# Cortex_M85 register map
Vendor: ARM Ltd.; File version: 1.0
Cortex-M85 core descriptions, generated from ARM developer studio
CPU: CM85 r0p0, little endian, MPU, FPU, vendor SysTick, 8 interrupt priority bits
Registers are 32-bit, read-write, no defined reset value unless marked. A register's access mark holds for its fields unless they carry their own. Offsets are from the block's base; lines under a group give offsets from that group; [hi:lo] are bit positions; {n}, {i} and the like mark numbered series; 'fields as' and 'values as' point back to an identical list; <NAME> marks a mode.

## Memory map
0xE000E004 ICB size 0x60 — Interrupt Control Registers
0xE000E010 SYST size 0x180 — SysTick Control Registers
0xE000E100 NVIC size 0x205DC — Nested Vectored Interrupt Controller registers
0xE000ED00 SCB size 0x20090 — System Control Block
0xE000ED90 MPU size 0x20038 — Memory protection Unit Control Registers
0xE000EDD0 SAU size 0xE0 — Security Attribute Unit
0xE000EDF0 DCB size 0x20010 — Debug Registers
0xE000EF00 SIG size 0x20004 — Software Interrupt Control
0xE000EF34 FPE size 0x20018 — Floating Point Control Registers

## DCB — Debug Registers
Base 0xE000EDF0
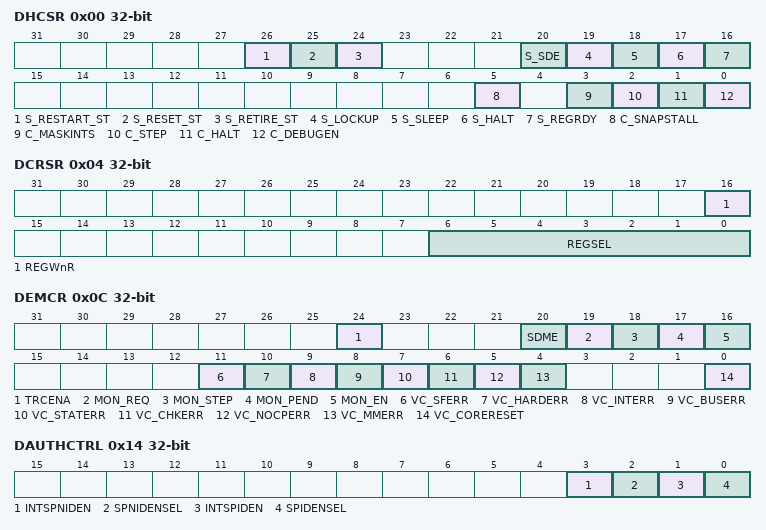
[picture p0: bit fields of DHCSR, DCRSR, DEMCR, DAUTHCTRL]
0x00 DHCSR
  [26] S_RESTART_ST, [25] S_RESET_ST, [24] S_RETIRE_ST, [20] S_SDE, [19] S_LOCKUP, [18] S_SLEEP, [17] S_HALT, [16] S_REGRDY, [5] C_SNAPSTALL, [3] C_MASKINTS, [2] C_STEP, [1] C_HALT, [0] C_DEBUGEN
0x04 DCRSR wo
  [16] REGWnR, [6:0] REGSEL
0x08 DCRDR
  [31:0] DBGTMP
0x0C DEMCR ro
  [24] TRCENA, [20] SDME, [19] MON_REQ, [18] MON_STEP, [17] MON_PEND, [16] MON_EN, [11] VC_SFERR, [10] VC_HARDERR, [9] VC_INTERR, [8] VC_BUSERR, [7] VC_STATERR, [6] VC_CHKERR, [5] VC_NOCPERR, [4] VC_MMERR, [0] VC_CORERESET
0x14 DAUTHCTRL
  [3] INTSPNIDEN, [2] SPNIDENSEL, [1] INTSPIDEN, [0] SPIDENSEL
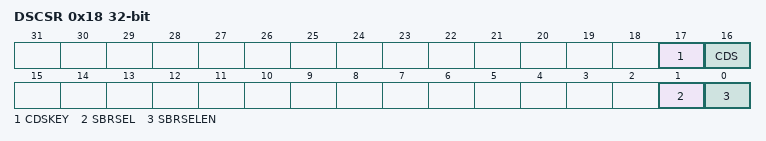
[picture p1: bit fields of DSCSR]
0x18 DSCSR ro
  [17] CDSKEY, [16] CDS, [1] SBRSEL, [0] SBRSELEN

## FPE — Floating Point Control Registers
Base 0xE000EF34
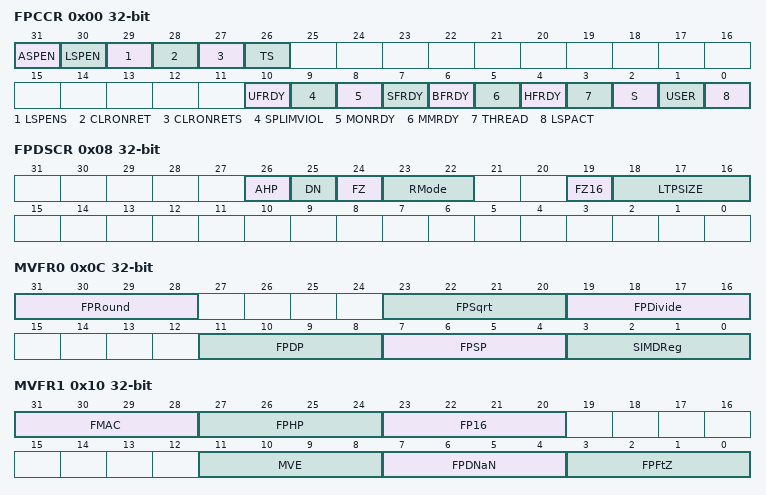
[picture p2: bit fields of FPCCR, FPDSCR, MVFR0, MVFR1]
0x00 FPCCR
  [31] ASPEN, [30] LSPEN, [29] LSPENS, [28] CLRONRET, [27] CLRONRETS, [26] TS, [10] UFRDY, [9] SPLIMVIOL, [8] MONRDY, [7] SFRDY, [6] BFRDY, [5] MMRDY, [4] HFRDY, [3] THREAD, [2] S, [1] USER, [0] LSPACT
0x04 FPCAR
  [31:3] ADDRESS
0x08 FPDSCR
  [26] AHP, [25] DN, [24] FZ, [23:22] RMode, [19] FZ16, [18:16] LTPSIZE
0x0C MVFR0 ro
  [31:28] FPRound, [23:20] FPSqrt, [19:16] FPDivide, [11:8] FPDP, [7:4] FPSP, [3:0] SIMDReg
0x10 MVFR1 ro
  [31:28] FMAC, [27:24] FPHP, [23:20] FP16, [11:8] MVE, [7:4] FPDNaN, [3:0] FPFtZ
0x14 MVFR2 ro
  [7:4] FPMisc

## ICB — Interrupt Control Registers
Base 0xE000E004
0x00 ICTR ro
  [3:0] INTLINESNUM
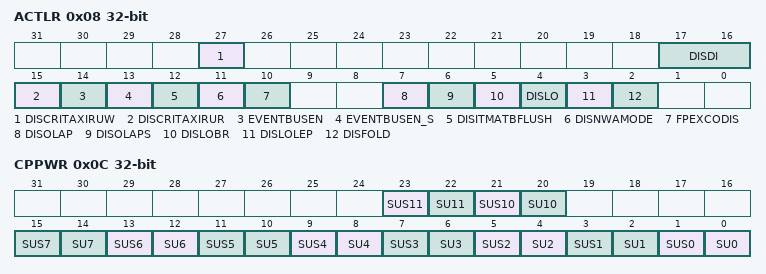
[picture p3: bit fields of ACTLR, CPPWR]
0x08 ACTLR
  [27] DISCRITAXIRUW, [17:16] DISDI, [15] DISCRITAXIRUR, [14] EVENTBUSEN, [13] EVENTBUSEN_S, [12] DISITMATBFLUSH, [11] DISNWAMODE, [10] FPEXCODIS, [7] DISOLAP, [6] DISOLAPS, [5] DISLOBR, [4] DISLO, [3] DISLOLEP, [2] DISFOLD
0x0C CPPWR
  [23] SUS11, [22] SU11, [21] SUS10, [20] SU10, [2n+1] SUS{n} (n=0..7), [2n] SU{n} (n=0..7)

## MPU — Memory protection Unit Control Registers
Base 0xE000ED90
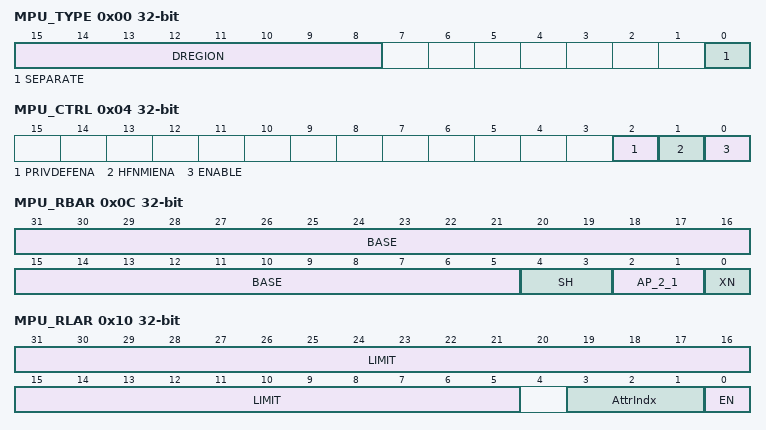
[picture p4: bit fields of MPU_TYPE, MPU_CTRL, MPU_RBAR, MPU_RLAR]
0x00 MPU_TYPE ro
  [15:8] DREGION
  [0] SEPARATE
    0=Uniform; 1=Separate
0x04 MPU_CTRL — MPU Control Register
  [2] PRIVDEFENA, [1] HFNMIENA, [0] ENABLE
0x08 MPU_RNR — MPU Region Number Register
  [7:0] REGION
0x0C MPU_RBAR — MPU Region Base Address Register
  [31:5] BASE, [4:3] SH, [2:1] AP_2_1, [0] XN
0x10 MPU_RLAR — MPU Region Limit Address Register
  [31:5] LIMIT, [3:1] AttrIndx, [0] EN
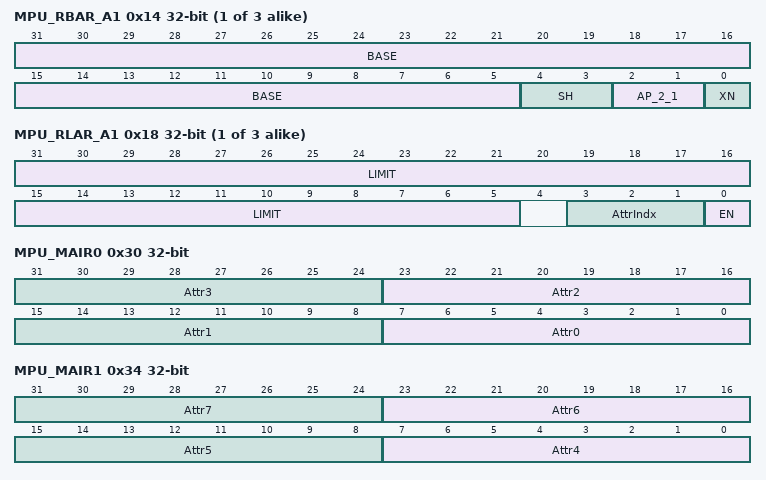
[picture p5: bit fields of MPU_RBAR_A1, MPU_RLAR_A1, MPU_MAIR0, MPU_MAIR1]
{0xC+8i} MPU_RBAR_A{i} (i=1..3) — MPU Region Base Address Register
  [31:5] BASE, [4:3] SH, [2:1] AP_2_1, [0] XN
{0x10+8i} MPU_RLAR_A{i} (i=1..3) — MPU Region Limit Address Register
  [31:5] LIMIT, [3:1] AttrIndx, [0] EN
0x30 MPU_MAIR0 — MPU Memory Attribute Indirection Register 0
  [8n+7:8n] Attr{n} (n=0..3)
0x34 MPU_MAIR1 — MPU Memory Attribute Indirection Register 1
  [8n-25:8n-32] Attr{n} (n=4..7)

## NVIC — Nested Vectored Interrupt Controller registers
Base 0xE000E100
{0x0+4i} NVIC_ISER{i} reset 0x0 (i=0..15) — Interrupt Set-Enable Register
  [31:0] SETENA
{0x80+4i} NVIC_ICER{i} reset 0x0 (i=0..15) — Interrupt Clear-Enable Register
  [31:0] CLRENA
{0x100+4i} NVIC_ISPR{i} reset 0x0 (i=0..15) — Interrupt Set-Pending Register
  [31:0] SETPEND
{0x180+4i} NVIC_ICPR{i} reset 0x0 (i=0..15) — Interrupt Clear-Pending Register
  [31:0] CLRPEND
{0x200+4i} NVIC_IABR{i} reset 0x0 (i=0..15) — Interrupt Active Bit Register
  [31:0] ACTIVE
{0x280+4i} ITNS{i} reset 0x0 (i=0..15) — Interrupt Target Non-secure Registers
  [31:0] ITNS
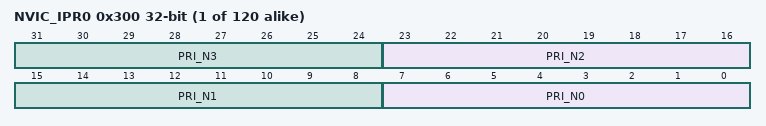
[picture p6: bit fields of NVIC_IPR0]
{0x300+4i} NVIC_IPR{i} (i=0..119)
  [8n+7:8n] PRI_N{n} (n=0..3)
0xE00 STIR ro
  [8:0] INTID

## Notices in the file
Copyright (c) 2024 STMicroelectronics.
SPDX-License-Identifier: Apache-2.0
Licensed under the Apache License, Version 2.0 (the "License");
you may not use this file except in compliance with the License.
You may obtain a copy of the License at
http://www.apache.org/licenses/LICENSE-2.0
Unless required by applicable law or agreed to in writing, software
distributed under the License is distributed on an "AS IS" BASIS,
WITHOUT WARRANTIES OR CONDITIONS OF ANY KIND, either express or implied.
See the License for the specific language governing permissions and
limitations under the License.
